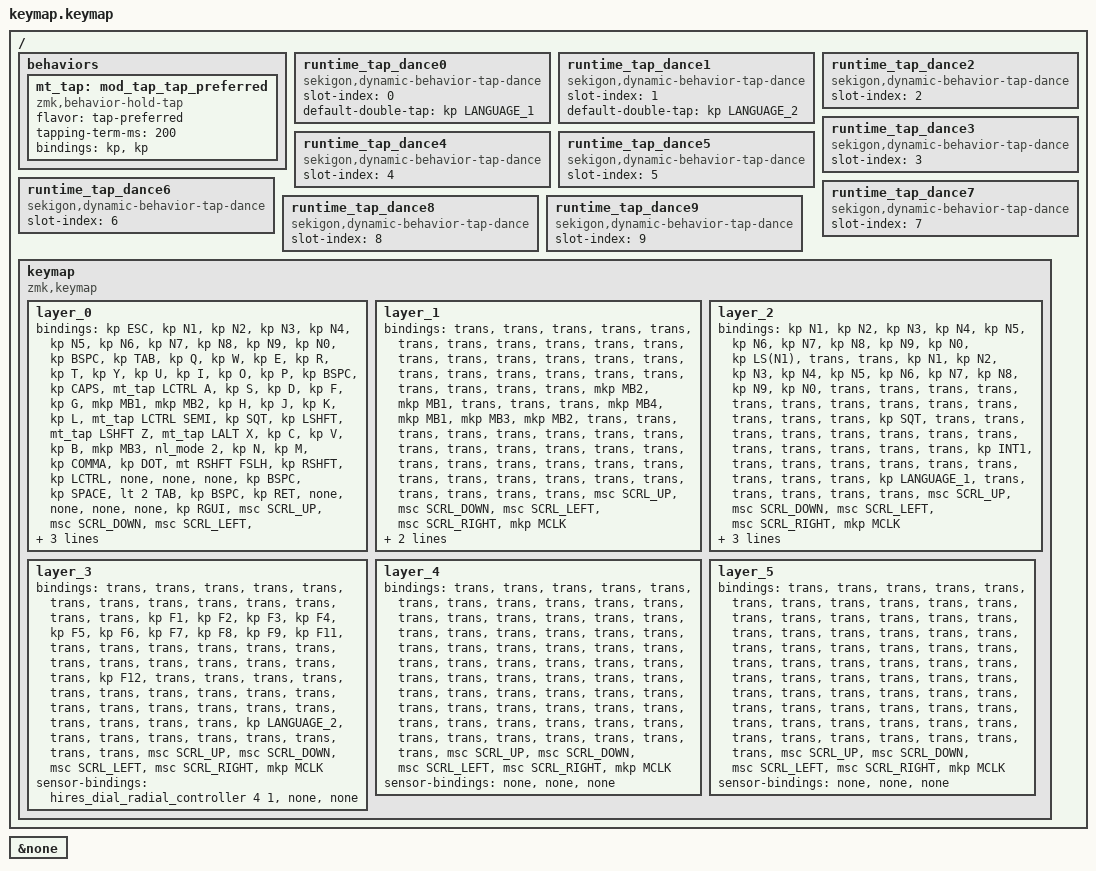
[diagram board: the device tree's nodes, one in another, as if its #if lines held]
#include <behaviors.dtsi>
#include <dt-bindings/zmk/bt.h>
#include <dt-bindings/zmk/keys.h>
#include <dt-bindings/zmk/outputs.h>
#include <dt-bindings/zmk/pointing.h>
#include <behaviors/nemu_link.dtsi>

#if defined(TORABO_TSUKI_LP_INPUT_HIRES_DIAL)
#include <behaviors/hires_dial.dtsi>
#endif

/ {
    behaviors {
        mt_tap: mod_tap_tap_preferred {
            compatible = "zmk,behavior-hold-tap";
            #binding-cells = <2>;
            flavor = "tap-preferred";
            tapping-term-ms = <200>;
            bindings = <&kp>, <&kp>;
        };
    };

    runtime_tap_dance0: runtime_tap_dance0 {
        compatible = "sekigon,dynamic-behavior-tap-dance";
        #binding-cells = <0>;
        slot-index = <0>;
        default-double-tap = <&kp LANGUAGE_1>;
    };

    runtime_tap_dance1: runtime_tap_dance1 {
        compatible = "sekigon,dynamic-behavior-tap-dance";
        #binding-cells = <0>;
        slot-index = <1>;
        default-double-tap = <&kp LANGUAGE_2>;
    };

    runtime_tap_dance2: runtime_tap_dance2 {
        compatible = "sekigon,dynamic-behavior-tap-dance";
        #binding-cells = <0>;
        slot-index = <2>;
    };

    runtime_tap_dance3: runtime_tap_dance3 {
        compatible = "sekigon,dynamic-behavior-tap-dance";
        #binding-cells = <0>;
        slot-index = <3>;
    };

    runtime_tap_dance4: runtime_tap_dance4 {
        compatible = "sekigon,dynamic-behavior-tap-dance";
        #binding-cells = <0>;
        slot-index = <4>;
    };

    runtime_tap_dance5: runtime_tap_dance5 {
        compatible = "sekigon,dynamic-behavior-tap-dance";
        #binding-cells = <0>;
        slot-index = <5>;
    };

    runtime_tap_dance6: runtime_tap_dance6 {
        compatible = "sekigon,dynamic-behavior-tap-dance";
        #binding-cells = <0>;
        slot-index = <6>;
    };

    runtime_tap_dance7: runtime_tap_dance7 {
        compatible = "sekigon,dynamic-behavior-tap-dance";
        #binding-cells = <0>;
        slot-index = <7>;
    };

    runtime_tap_dance8: runtime_tap_dance8 {
        compatible = "sekigon,dynamic-behavior-tap-dance";
        #binding-cells = <0>;
        slot-index = <8>;
    };

    runtime_tap_dance9: runtime_tap_dance9 {
        compatible = "sekigon,dynamic-behavior-tap-dance";
        #binding-cells = <0>;
        slot-index = <9>;
    };

    keymap {
        compatible = "zmk,keymap";

        layer_0 {
            bindings = <
&kp ESC  &kp N1  &kp N2  &kp N3  &kp N4  &kp N5  &kp N6  &kp N7  &kp N8  &kp N9  &kp N0  &kp BSPC
&kp TAB  &kp Q  &kp W  &kp E  &kp R  &kp T  &kp Y  &kp U  &kp I  &kp O  &kp P  &kp BSPC
&kp CAPS  &mt_tap LCTRL A  &kp S  &kp D  &kp F  &kp G  &mkp MB1  &mkp MB2  &kp H  &kp J  &kp K  &kp L  &mt_tap LCTRL SEMI  &kp SQT
&kp LSHFT  &mt_tap LSHFT Z  &mt_tap LALT X  &kp C  &kp V  &kp B  &mkp MB3  &nl_mode 2  &kp N  &kp M  &kp COMMA  &kp DOT  &mt RSHFT FSLH  &kp RSHFT
&kp LCTRL  &none  &none  &none  &kp BSPC  &kp SPACE  &lt 2 TAB  &kp BSPC  &kp RET  &none  &none  &none  &none  &kp RGUI
#if defined(TORABO_TSUKI_LP_KSCAN_4_DIRECTION_SWITCH)
&msc SCRL_UP &msc SCRL_DOWN &msc SCRL_LEFT &msc SCRL_RIGHT &mkp MCLK
#elif defined(TORABO_TSUKI_LP_INPUT_HIRES_DIAL)
&mkp MB3
#endif
            >;
        };

        layer_1 {
            bindings = <

&trans  &trans  &trans  &trans  &trans  &trans  &trans  &trans  &trans  &trans  &trans  &trans
&trans  &trans  &trans  &trans  &trans  &trans  &trans  &trans  &trans  &trans  &trans  &trans
&trans  &trans  &trans  &mkp MB2  &mkp MB1  &trans  &trans  &trans  &mkp MB4  &mkp MB1  &mkp MB3  &mkp MB2  &trans  &trans
&trans  &trans  &trans  &trans  &trans  &trans  &trans  &trans  &trans  &trans  &trans  &trans  &trans  &trans
&trans  &trans  &trans  &trans  &trans  &trans  &trans  &trans  &trans  &trans  &trans  &trans  &trans  &trans
#if defined(TORABO_TSUKI_LP_KSCAN_4_DIRECTION_SWITCH)
&msc SCRL_UP &msc SCRL_DOWN &msc SCRL_LEFT &msc SCRL_RIGHT &mkp MCLK
#elif defined(TORABO_TSUKI_LP_INPUT_HIRES_DIAL)
&mkp MB3
#endif
            >;
        };

        layer_2 {
            bindings = <

&kp N1  &kp N2  &kp N3  &kp N4  &kp N5  &kp N6  &kp N7  &kp N8  &kp N9  &kp N0  &kp LS(N1)  &trans
&trans  &kp N1  &kp N2  &kp N3  &kp N4  &kp N5  &kp N6  &kp N7  &kp N8  &kp N9  &kp N0  &trans
&trans  &trans  &trans  &trans  &trans  &trans  &trans  &trans  &trans  &trans  &trans  &trans  &kp SQT  &trans
&trans  &trans  &trans  &trans  &trans  &trans  &trans  &trans  &trans  &trans  &trans  &trans  &kp INT1  &trans
&trans  &trans  &trans  &trans  &trans  &trans  &trans  &trans  &kp LANGUAGE_1  &trans  &trans  &trans  &trans  &trans
#if defined(TORABO_TSUKI_LP_KSCAN_4_DIRECTION_SWITCH)
&msc SCRL_UP &msc SCRL_DOWN &msc SCRL_LEFT &msc SCRL_RIGHT &mkp MCLK
#elif defined(TORABO_TSUKI_LP_INPUT_HIRES_DIAL)
&kp C_MUTE
#endif
            >;
        };

        layer_3 {
            bindings = <

&trans  &trans  &trans  &trans  &trans  &trans  &trans  &trans  &trans  &trans  &trans  &trans
&trans  &kp F1  &kp F2  &kp F3  &kp F4  &kp F5  &kp F6  &kp F7  &kp F8  &kp F9  &kp F11  &trans
&trans  &trans  &trans  &trans  &trans  &trans  &trans  &trans  &trans  &trans  &trans  &trans  &kp F12  &trans
&trans  &trans  &trans  &trans  &trans  &trans  &trans  &trans  &trans  &trans  &trans  &trans  &trans  &trans
&trans  &trans  &trans  &trans  &trans  &kp LANGUAGE_2  &trans  &trans  &trans  &trans  &trans  &trans  &trans  &trans
#if defined(TORABO_TSUKI_LP_KSCAN_4_DIRECTION_SWITCH)
&msc SCRL_UP &msc SCRL_DOWN &msc SCRL_LEFT &msc SCRL_RIGHT &mkp MCLK
#elif defined(TORABO_TSUKI_LP_INPUT_HIRES_DIAL)
&hires_dial_radial_controller_button
#endif
            >;
        };

        layer_4 {
            bindings = <
&trans  &trans  &trans  &trans  &trans  &trans  &trans  &trans  &trans  &trans  &trans  &trans
&trans  &trans  &trans  &trans  &trans  &trans  &trans  &trans  &trans  &trans  &trans  &trans
&trans  &trans  &trans  &trans  &trans  &trans  &trans  &trans  &trans  &trans  &trans  &trans  &trans  &trans
&trans  &trans  &trans  &trans  &trans  &trans  &trans  &trans  &trans  &trans  &trans  &trans  &trans  &trans
&trans  &trans  &trans  &trans  &trans  &trans  &trans  &trans  &trans  &trans  &trans  &trans  &trans  &trans
#if defined(TORABO_TSUKI_LP_KSCAN_4_DIRECTION_SWITCH)
&msc SCRL_UP &msc SCRL_DOWN &msc SCRL_LEFT &msc SCRL_RIGHT &mkp MCLK
#elif defined(TORABO_TSUKI_LP_INPUT_HIRES_DIAL)
&mkp MB3
#endif
            >;
        };

        layer_5 {
            bindings = <
&trans  &trans  &trans  &trans  &trans  &trans  &trans  &trans  &trans  &trans  &trans  &trans
&trans  &trans  &trans  &trans  &trans  &trans  &trans  &trans  &trans  &trans  &trans  &trans
&trans  &trans  &trans  &trans  &trans  &trans  &trans  &trans  &trans  &trans  &trans  &trans  &trans  &trans
&trans  &trans  &trans  &trans  &trans  &trans  &trans  &trans  &trans  &trans  &trans  &trans  &trans  &trans
&trans  &trans  &trans  &trans  &trans  &trans  &trans  &trans  &trans  &trans  &trans  &trans  &trans  &trans
#if defined(TORABO_TSUKI_LP_KSCAN_4_DIRECTION_SWITCH)
&msc SCRL_UP &msc SCRL_DOWN &msc SCRL_LEFT &msc SCRL_RIGHT &mkp MCLK
#elif defined(TORABO_TSUKI_LP_INPUT_HIRES_DIAL)
&mkp MB3
#endif
            >;
        };
    };
};

#if defined(TORABO_TSUKI_LP_INPUT_HIRES_DIAL)
&none {
    #sensor-binding-cells = <0>;
};

&{/keymap/layer_0} {
    sensor-bindings = <&hires_dial_scroll 1 1 &none &none>;
};

&{/keymap/layer_1} {
    sensor-bindings = <&hires_dial_scroll 10 1 &none &none>;
};

&{/keymap/layer_2} {
    sensor-bindings = <&hires_dial_encoder C_VOL_UP C_VOL_DN &none &none>;
};

&{/keymap/layer_3} {
    /* Quarter-speed Radial Controller motion: output/input = 1/4. */
    sensor-bindings = <&hires_dial_radial_controller 4 1 &none &none>;
};

&{/keymap/layer_4} {
    sensor-bindings = <&none &none &none>;
};

&{/keymap/layer_5} {
    sensor-bindings = <&none &none &none>;
};
#endif
